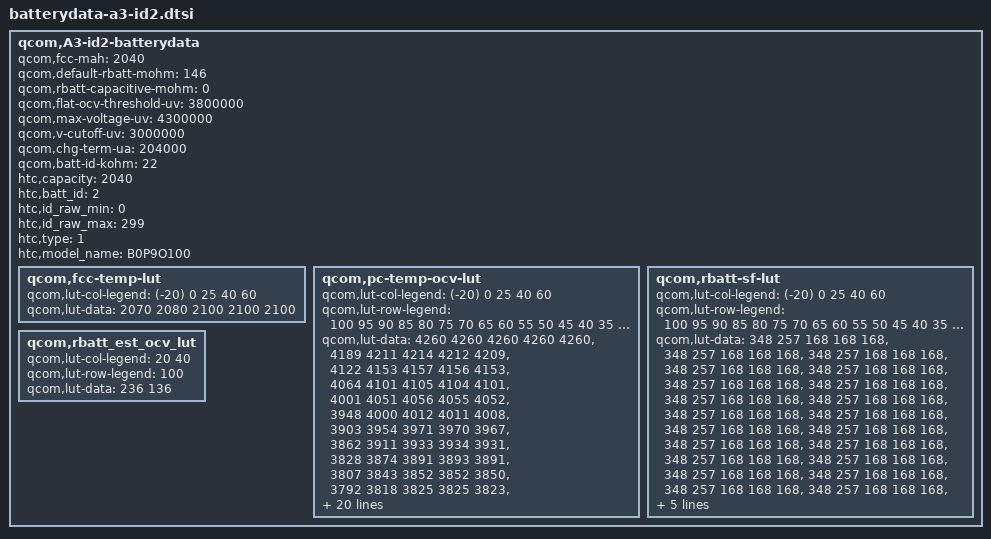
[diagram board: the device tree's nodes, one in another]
qcom,A3-id2-batterydata {
	qcom,fcc-mah = <2040>;
	qcom,default-rbatt-mohm = <146>;
	qcom,rbatt-capacitive-mohm = <0>;
	qcom,flat-ocv-threshold-uv = <3800000>;
	qcom,max-voltage-uv = <4300000>;
	qcom,v-cutoff-uv = <3000000>;
	qcom,chg-term-ua = <204000>;
	qcom,batt-id-kohm = <22>;
	htc,capacity = <2040>;
	htc,batt_id = <2>;
	htc,id_raw_min = <0>;
	htc,id_raw_max = <299>;
	htc,type = <1>;
	htc,model_name = "B0P9O100";

	qcom,fcc-temp-lut {
		qcom,lut-col-legend = <(-20) 0 25 40 60>;
		qcom,lut-data = <2070 2080 2100 2100 2100>;
	};

	qcom,pc-temp-ocv-lut {
		qcom,lut-col-legend = <(-20) 0 25 40 60>;
		qcom,lut-row-legend = <100 95 90 85 80 75 70 65 60 55 50 45 40 35 30 25 20 16 13 11 10 9 8 7 6 5 4 3 2 1 0>;
		qcom,lut-data = <4260 4260 4260 4260 4260>,
				<4189 4211 4214 4212 4209>,
				<4122 4153 4157 4156 4153>,
				<4064 4101 4105 4104 4101>,
				<4001 4051 4056 4055 4052>,
				<3948 4000 4012 4011 4008>,
				<3903 3954 3971 3970 3967>,
				<3862 3911 3933 3934 3931>,
				<3828 3874 3891 3893 3891>,
				<3807 3843 3852 3852 3850>,
				<3792 3818 3825 3825 3823>,
				<3778 3796 3804 3804 3802>,
				<3765 3780 3788 3788 3786>,
				<3751 3769 3775 3775 3772>,
				<3736 3758 3762 3758 3750>,
				<3719 3744 3745 3737 3725>,
				<3700 3725 3727 3718 3705>,
				<3679 3700 3707 3698 3686>,
				<3660 3686 3687 3679 3667>,
				<3643 3677 3677 3670 3659>,
				<3632 3673 3673 3668 3656>,
				<3619 3668 3670 3665 3654>,
				<3604 3662 3666 3660 3649>,
				<3586 3651 3659 3652 3640>,
				<3564 3631 3641 3632 3616>,
				<3536 3599 3603 3593 3578>,
				<3502 3556 3554 3543 3530>,
				<3457 3501 3492 3482 3470>,
				<3394 3424 3411 3402 3391>,
				<3283 3300 3290 3281 3274>,
				<3000 3000 3000 3000 3000>;
	};

	qcom,rbatt-sf-lut {
		qcom,lut-col-legend = <(-20) 0 25 40 60>;
		qcom,lut-row-legend = <100 95 90 85 80 75 70 65 60 55 50 45 40 35 30 25 20 16 13 11 10 9 8 7 6 5 4 3 2 1>;
		qcom,lut-data = <348 257 168 168 168>,
				<348 257 168 168 168>,
				<348 257 168 168 168>,
				<348 257 168 168 168>,
				<348 257 168 168 168>,
				<348 257 168 168 168>,
				<348 257 168 168 168>,
				<348 257 168 168 168>,
				<348 257 168 168 168>,
				<348 257 168 168 168>,
				<348 257 168 168 168>,
				<348 257 168 168 168>,
				<348 257 168 168 168>,
				<348 257 168 168 168>,
				<348 257 168 168 168>,
				<348 257 168 168 168>,
				<348 257 168 168 168>,
				<348 257 168 168 168>,
				<348 257 168 168 168>,
				<348 257 168 168 168>,
				<348 257 168 168 168>,
				<348 257 168 168 168>,
				<348 257 168 168 168>,
				<348 257 168 168 168>,
				<348 257 168 168 168>,
				<348 257 168 168 168>,
				<348 257 168 168 168>,
				<348 257 168 168 168>,
				<348 257 168 168 168>,
				<348 257 168 168 168>;
	};
	qcom,rbatt_est_ocv_lut {
		qcom,lut-col-legend = <20 40>;
		qcom,lut-row-legend = <100>;
		qcom,lut-data = <236 136>;
	};
};
